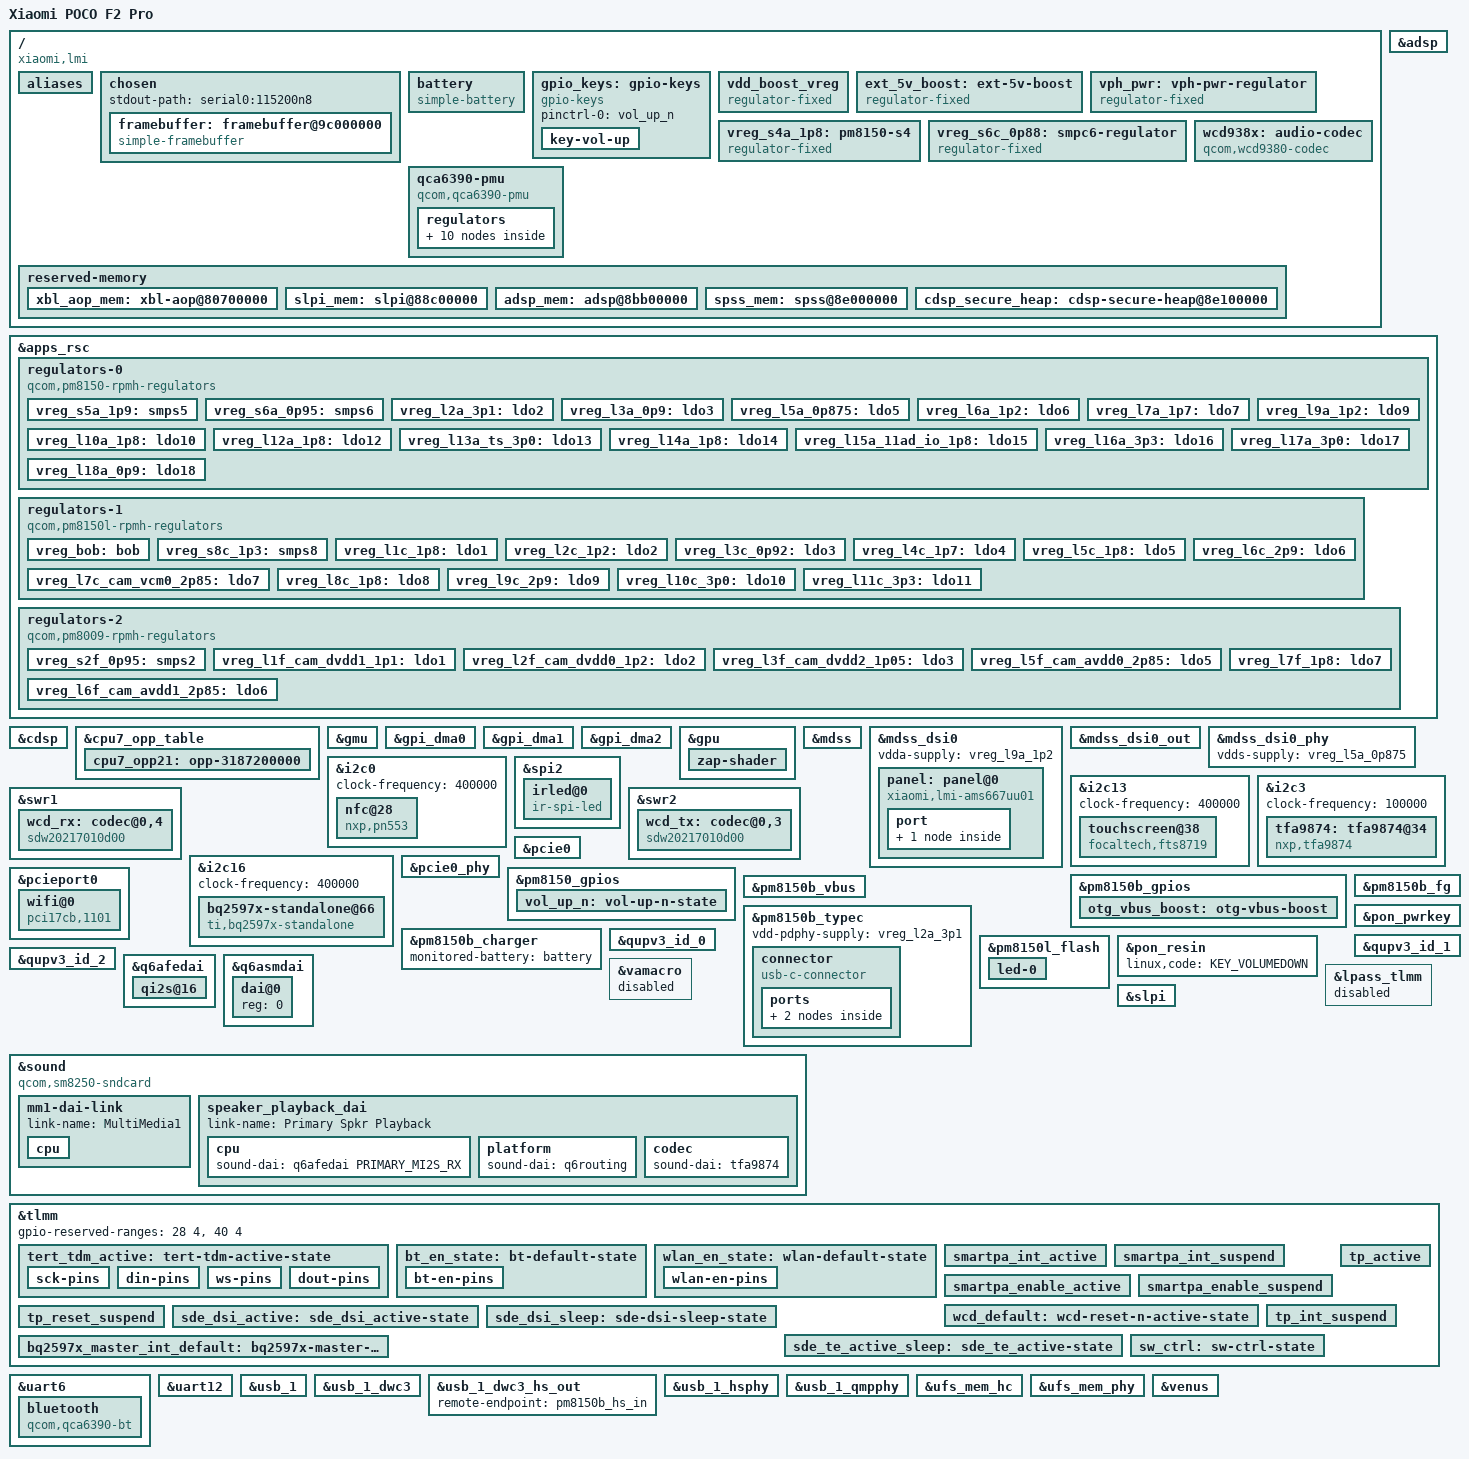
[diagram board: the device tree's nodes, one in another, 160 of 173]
// SPDX-License-Identifier: GPL-2.0-only OR BSD-2-Clause
/*
 * Copyright (c) 2025 Vitalii Skorkin <nikroks@mainlining.org>
 */

/dts-v1/;

#include <dt-bindings/arm/qcom,ids.h>
#include <dt-bindings/leds/common.h>
#include <dt-bindings/media/video-interfaces.h>
#include <dt-bindings/phy/phy.h>
#include <dt-bindings/regulator/qcom,rpmh-regulator.h>
#include <dt-bindings/sound/qcom,q6afe.h>
#include <dt-bindings/sound/qcom,q6asm.h>
#include <dt-bindings/usb/pd.h>
#include "sm8250.dtsi"
#include "pm8150.dtsi"
#include "pm8150b.dtsi"
#include "pm8150l.dtsi"
#include "pm8009.dtsi"

/*
 * Delete following upstream (sm8250.dtsi) reserved
 * memory mappings which are different on this device.
 */
/delete-node/ &adsp_mem;
/delete-node/ &cdsp_secure_heap;
/delete-node/ &slpi_mem;
/delete-node/ &spss_mem;
/delete-node/ &xbl_aop_mem;

/ {

	model = "Xiaomi POCO F2 Pro";
	compatible = "xiaomi,lmi", "qcom,sm8250";
	chassis-type = "handset";

	/* required for bootloader to select correct board */
	qcom,msm-id = <QCOM_ID_SM8250 0x20001>; /* SM8250 v2.1 */
	qcom,board-id = <37 0>;

	aliases {
		serial0 = &uart12;
     serial1 = &uart6;
	};

	chosen {
		#address-cells = <2>;
		#size-cells = <2>;
		ranges;
   stdout-path = "serial0:115200n8";
    
   framebuffer: framebuffer@9c000000 {
			compatible = "simple-framebuffer";
			reg = <0x0 0x9c000000 0x0 0x2300000>;
			width = <1080>;
			height = <2400>;
			stride = <(1080 * 4)>;
			format = "a8r8g8b8";
		};
	};

	battery: battery {
		compatible = "simple-battery";
		charge-full-design-microamp-hours = <4700000>;
		energy-full-design-microwatt-hours = <17500000>;
		voltage-min-design-microvolt = <3400000>;
		voltage-max-design-microvolt = <4460000>;
	};

	gpio_keys: gpio-keys {
		compatible = "gpio-keys";

		pinctrl-0 = <&vol_up_n>;
		pinctrl-names = "default";

		key-vol-up {
			label = "Volume Up";
			gpios = <&pm8150_gpios 6 GPIO_ACTIVE_LOW>;
			linux,code = <KEY_VOLUMEUP>;
			debounce-interval = <15>;
			linux,can-disable;
			wakeup-source;
		};
	};
  
  vdd_boost_vreg: vdd_boost_vreg {
		compatible = "regulator-fixed";
		regulator-name = "vdd_boost_vreg";
		regulator-min-microvolt = <5000000>;
		regulator-max-microvolt = <5000000>;
		startup-delay-us = <4000>;
		enable-active-high;
		regulator-always-on;
		gpio = <&pm8150b_gpios 5 0>;
	 };

	ext_5v_boost: ext-5v-boost {
		status = "okay";
		compatible = "regulator-fixed";
		gpio = <&pm8150b_gpios 12 GPIO_ACTIVE_HIGH>;
		pinctrl-names = "default";
		pinctrl-0 = <&otg_vbus_boost>;
		regulator-min-microvolt = <5000000>;
		regulator-max-microvolt = <5000000>;
		regulator-enable-ramp-delay = <1600>;
		regulator-name = "ext_5v_boost";
		enable-active-high;
	};

	vph_pwr: vph-pwr-regulator {
		compatible = "regulator-fixed";
		regulator-name = "vph_pwr";
		regulator-min-microvolt = <3700000>;
		regulator-max-microvolt = <3700000>;
	};
   
   vreg_s4a_1p8: pm8150-s4 {
		compatible = "regulator-fixed";
		regulator-name = "vreg_s4a_1p8";

		regulator-min-microvolt = <1800000>;
		regulator-max-microvolt = <1800000>;

		regulator-always-on;
		regulator-boot-on;

		vin-supply = <&vph_pwr>;
	};

	/* S6c is really ebi.lvl but it's there for supply map completeness sake. */
	vreg_s6c_0p88: smpc6-regulator {
		compatible = "regulator-fixed";
		regulator-name = "vreg_s6c_0p88";
		regulator-min-microvolt = <880000>;
		regulator-max-microvolt = <880000>;
		regulator-always-on;
		vin-supply = <&vph_pwr>;
	};
  
   wcd938x: audio-codec {
		compatible = "qcom,wcd9380-codec";
		
		pinctrl-names = "default";
		pinctrl-0 = <&wcd_default>;
		
		qcom,micbias1-microvolt = <2750000>;
		qcom,micbias2-microvolt = <2750000>;
		qcom,micbias3-microvolt = <2750000>;
		qcom,micbias4-microvolt = <2750000>;
		qcom,mbhc-buttons-vthreshold-microvolt = <75000 150000 237000 500000 500000 500000 500000 500000>;
		qcom,mbhc-headset-vthreshold-microvolt = <1700000>;
		qcom,mbhc-headphone-vthreshold-microvolt = <50000>;
		qcom,rx-device = <&wcd_rx>;
		qcom,tx-device = <&wcd_tx>;
		
		reset-gpios = <&tlmm 108 GPIO_ACTIVE_LOW>;
		
		vdd-buck-supply = <&vreg_s4a_1p8>;
		vdd-rxtx-supply = <&vreg_s4a_1p8>;
		vdd-io-supply = <&vreg_s4a_1p8>;
		vdd-mic-bias-supply = <&vreg_bob>;
		
		#sound-dai-cells = <1>;
	};

	qca6390-pmu {
		compatible = "qcom,qca6390-pmu";

		pinctrl-names = "default";
		pinctrl-0 = <&bt_en_state>, <&wlan_en_state>;

		vddaon-supply = <&vreg_s6a_0p95>;
		vddpmu-supply = <&vreg_s2f_0p95>;
		vddrfa0p95-supply = <&vreg_s2f_0p95>;
		vddrfa1p3-supply = <&vreg_s8c_1p3>;
		vddrfa1p9-supply = <&vreg_s5a_1p9>;
		vddpcie1p3-supply = <&vreg_s8c_1p3>;
		vddpcie1p9-supply = <&vreg_s5a_1p9>;
		vddio-supply = <&vreg_s4a_1p8>;

		wlan-enable-gpios = <&tlmm 20 GPIO_ACTIVE_HIGH>;
		bt-enable-gpios = <&tlmm 21 GPIO_ACTIVE_HIGH>;

		regulators {
			vreg_pmu_rfa_cmn: ldo0 {
				regulator-name = "vreg_pmu_rfa_cmn";
			};

			vreg_pmu_aon_0p59: ldo1 {
				regulator-name = "vreg_pmu_aon_0p59";
			};

			vreg_pmu_wlcx_0p8: ldo2 {
				regulator-name = "vreg_pmu_wlcx_0p8";
			};

			vreg_pmu_wlmx_0p85: ldo3 {
				regulator-name = "vreg_pmu_wlmx_0p85";
			};

			vreg_pmu_btcmx_0p85: ldo4 {
				regulator-name = "vreg_pmu_btcmx_0p85";
			};

			vreg_pmu_rfa_0p8: ldo5 {
				regulator-name = "vreg_pmu_rfa_0p8";
			};

			vreg_pmu_rfa_1p2: ldo6 {
				regulator-name = "vreg_pmu_rfa_1p2";
			};

			vreg_pmu_rfa_1p7: ldo7 {
				regulator-name = "vreg_pmu_rfa_1p7";
			};

			vreg_pmu_pcie_0p9: ldo8 {
				regulator-name = "vreg_pmu_pcie_0p9";
			};

			vreg_pmu_pcie_1p8: ldo9 {
				regulator-name = "vreg_pmu_pcie_1p8";
			};
		};
	};

	reserved-memory {
		xbl_aop_mem: xbl-aop@80700000 {
			reg = <0x0 0x80600000 0x0 0x260000>;
			no-map;
		};

		slpi_mem: slpi@88c00000 {
			reg = <0x0 0x88c00000 0x0 0x2f00000>;
			no-map;
		};

		adsp_mem: adsp@8bb00000 {
			reg = <0x0 0x8bb00000 0x0 0x2500000>;
			no-map;
		};

		spss_mem: spss@8e000000 {
			reg = <0x0 0x8e000000 0x0 0x100000>;
			no-map;
		};

		cdsp_secure_heap: cdsp-secure-heap@8e100000 {
			reg = <0x0 0x8e100000 0x0 0x4600000>;
			no-map;
		};
	};
};

&adsp {
	firmware-name = "qcom/sm8250/xiaomi/alioth/adsp.mbn";
	status = "okay";
};

&apps_rsc {
	regulators-0 {
		compatible = "qcom,pm8150-rpmh-regulators";
		qcom,pmic-id = "a";

		vdd-s1-supply = <&vph_pwr>;
		vdd-s2-supply = <&vph_pwr>;
		vdd-s3-supply = <&vph_pwr>;
		vdd-s4-supply = <&vph_pwr>;
		vdd-s5-supply = <&vph_pwr>;
		vdd-s6-supply = <&vph_pwr>;
		vdd-s7-supply = <&vph_pwr>;
		vdd-s8-supply = <&vph_pwr>;
		vdd-s9-supply = <&vph_pwr>;
		vdd-s10-supply = <&vph_pwr>;
		vdd-l1-l8-l11-supply = <&vreg_s6c_0p88>;
		vdd-l2-l10-supply = <&vreg_bob>;
		vdd-l3-l4-l5-l18-supply = <&vreg_s6a_0p95>;
		vdd-l6-l9-supply = <&vreg_s8c_1p3>;
		vdd-l7-l12-l14-l15-supply = <&vreg_s5a_1p9>;
		vdd-l13-l16-l17-supply = <&vreg_bob>;

		vreg_s5a_1p9: smps5 {
			regulator-name = "vreg_s5a_1p9";
			regulator-min-microvolt = <1904000>;
			regulator-max-microvolt = <2000000>;
			regulator-initial-mode = <RPMH_REGULATOR_MODE_HPM>;
		};

		vreg_s6a_0p95: smps6 {
			regulator-name = "vreg_s6a_0p95";
			regulator-min-microvolt = <920000>;
			regulator-max-microvolt = <1128000>;
			regulator-initial-mode = <RPMH_REGULATOR_MODE_HPM>;
		};

		vreg_l2a_3p1: ldo2 {
			regulator-name = "vreg_l2a_3p1";
			regulator-min-microvolt = <3072000>;
			regulator-max-microvolt = <3072000>;
			regulator-initial-mode = <RPMH_REGULATOR_MODE_HPM>;
		};

		vreg_l3a_0p9: ldo3 {
			regulator-name = "vreg_l3a_0p9";
			regulator-min-microvolt = <928000>;
			regulator-max-microvolt = <932000>;
			regulator-initial-mode = <RPMH_REGULATOR_MODE_HPM>;
		};

		vreg_l5a_0p875: ldo5 {
			regulator-name = "vreg_l5a_0p875";
			regulator-min-microvolt = <880000>;
			regulator-max-microvolt = <880000>;
			regulator-initial-mode = <RPMH_REGULATOR_MODE_HPM>;
		};

		vreg_l6a_1p2: ldo6 {
			regulator-name = "vreg_l6a_1p2";
			regulator-min-microvolt = <1200000>;
			regulator-max-microvolt = <1200000>;
			regulator-initial-mode = <RPMH_REGULATOR_MODE_HPM>;
		};

		vreg_l7a_1p7: ldo7 {
			regulator-name = "vreg_l7a_1p7";
			regulator-min-microvolt = <1704000>;
			regulator-max-microvolt = <1800000>;
			regulator-initial-mode = <RPMH_REGULATOR_MODE_HPM>;
		};

		vreg_l9a_1p2: ldo9 {
			regulator-name = "vreg_l9a_1p2";
			regulator-min-microvolt = <1200000>;
			regulator-max-microvolt = <1200000>;
			regulator-initial-mode = <RPMH_REGULATOR_MODE_HPM>;
		};

		vreg_l10a_1p8: ldo10 {
			regulator-name = "vreg_l10a_1p8";
			regulator-min-microvolt = <1800000>;
			regulator-max-microvolt = <1800000>;
			regulator-initial-mode = <RPMH_REGULATOR_MODE_HPM>;
		};

		vreg_l12a_1p8: ldo12 {
			regulator-name = "vreg_l12a_1p8";
			regulator-min-microvolt = <1800000>;
			regulator-max-microvolt = <1800000>;
			regulator-initial-mode = <RPMH_REGULATOR_MODE_HPM>;
		};

		vreg_l13a_ts_3p0: ldo13 {
			regulator-name = "vreg_l13a_ts_3p0";
			regulator-min-microvolt = <3008000>;
			regulator-max-microvolt = <3008000>;
			regulator-initial-mode = <RPMH_REGULATOR_MODE_HPM>;
		};

		vreg_l14a_1p8: ldo14 {
			regulator-name = "vreg_l14a_1p8";
			regulator-min-microvolt = <1800000>;
			regulator-max-microvolt = <1880000>;
			regulator-initial-mode = <RPMH_REGULATOR_MODE_HPM>;
		};

		vreg_l15a_11ad_io_1p8: ldo15 {
			regulator-name = "vreg_l15a_11ad_io_1p8";
			regulator-min-microvolt = <1800000>;
			regulator-max-microvolt = <1800000>;
			regulator-initial-mode = <RPMH_REGULATOR_MODE_HPM>;
		};

		vreg_l16a_3p3: ldo16 {
			regulator-name = "vreg_l16a_3p3";
			regulator-min-microvolt = <3024000>;
			regulator-max-microvolt = <3304000>;
			regulator-initial-mode = <RPMH_REGULATOR_MODE_HPM>;
		};

		vreg_l17a_3p0: ldo17 {
			regulator-name = "vreg_l17a_3p0";
			regulator-min-microvolt = <2856000>;
			regulator-max-microvolt = <3008000>;
			regulator-initial-mode = <RPMH_REGULATOR_MODE_HPM>;
		};

		vreg_l18a_0p9: ldo18 {
			regulator-name = "vreg_l18a_0p9";
			regulator-min-microvolt = <912000>;
			regulator-max-microvolt = <912000>;
			regulator-initial-mode = <RPMH_REGULATOR_MODE_HPM>;
		};
	};

	regulators-1 {
		compatible = "qcom,pm8150l-rpmh-regulators";
		qcom,pmic-id = "c";

		vdd-s1-supply = <&vph_pwr>;
		vdd-s2-supply = <&vph_pwr>;
		vdd-s3-supply = <&vph_pwr>;
		vdd-s4-supply = <&vph_pwr>;
		vdd-s5-supply = <&vph_pwr>;
		vdd-s6-supply = <&vph_pwr>;
		vdd-s7-supply = <&vph_pwr>;
		vdd-s8-supply = <&vph_pwr>;
		vdd-l1-l8-supply = <&vreg_s4a_1p8>;
		vdd-l2-l3-supply = <&vreg_s8c_1p3>;
		vdd-l4-l5-l6-supply = <&vreg_bob>;
		vdd-l7-l11-supply = <&vreg_bob>;
		vdd-l9-l10-supply = <&vreg_bob>;
		vdd-bob-supply = <&vph_pwr>;

		vreg_bob: bob {
			regulator-name = "vreg_bob";
			regulator-min-microvolt = <3008000>;
			regulator-max-microvolt = <4000000>;
			regulator-initial-mode = <RPMH_REGULATOR_MODE_AUTO>;
		};

		vreg_s8c_1p3: smps8 {
			regulator-name = "vreg_s8c_1p3";
			regulator-min-microvolt = <1352000>;
			regulator-max-microvolt = <1352000>;
			regulator-initial-mode = <RPMH_REGULATOR_MODE_HPM>;
		};

		vreg_l1c_1p8: ldo1 {
			regulator-name = "vreg_l1c_1p8";
			regulator-min-microvolt = <1800000>;
			regulator-max-microvolt = <1800000>;
			regulator-initial-mode = <RPMH_REGULATOR_MODE_HPM>;
			// regulator-always-on;
			// regulator-boot-on;
		};

		vreg_l2c_1p2: ldo2 {
			regulator-name = "vreg_l2c_1p2";
			regulator-min-microvolt = <1200000>;
			regulator-max-microvolt = <1200000>;
			regulator-initial-mode = <RPMH_REGULATOR_MODE_HPM>;
		};

		vreg_l3c_0p92: ldo3 {
			regulator-name = "vreg_l3c_0p92";
			regulator-min-microvolt = <920000>;
			regulator-max-microvolt = <920000>;
			regulator-initial-mode = <RPMH_REGULATOR_MODE_HPM>;
		};

		vreg_l4c_1p7: ldo4 {
			regulator-name = "vreg_l4c_1p7";
			regulator-min-microvolt = <1704000>;
			regulator-max-microvolt = <2928000>;
			regulator-initial-mode = <RPMH_REGULATOR_MODE_HPM>;
		};

		vreg_l5c_1p8: ldo5 {
			regulator-name = "vreg_l5c_1p8";
			regulator-min-microvolt = <1800000>;
			regulator-max-microvolt = <2928000>;
			regulator-initial-mode = <RPMH_REGULATOR_MODE_HPM>;
		};

		vreg_l6c_2p9: ldo6 {
			regulator-name = "vreg_l6c_2p9";
			regulator-min-microvolt = <1800000>;
			regulator-max-microvolt = <2960000>;
			regulator-initial-mode = <RPMH_REGULATOR_MODE_HPM>;
		};

		vreg_l7c_cam_vcm0_2p85: ldo7 {
			regulator-name = "vreg_l7c_cam_vcm0_2p85";
			regulator-min-microvolt = <2856000>;
			regulator-max-microvolt = <3104000>;
			regulator-initial-mode = <RPMH_REGULATOR_MODE_HPM>;
		};

		vreg_l8c_1p8: ldo8 {
			regulator-name = "vreg_l8c_1p8";
			regulator-min-microvolt = <1800000>;
			regulator-max-microvolt = <1800000>;
			regulator-initial-mode = <RPMH_REGULATOR_MODE_HPM>;
		};

		vreg_l9c_2p9: ldo9 {
			regulator-name = "vreg_l9c_2p9";
			regulator-min-microvolt = <2704000>;
			regulator-max-microvolt = <2960000>;
			regulator-initial-mode = <RPMH_REGULATOR_MODE_HPM>;
		};

		vreg_l10c_3p0: ldo10 {
			regulator-name = "vreg_l10c_3p0";
			regulator-min-microvolt = <3000000>;
			regulator-max-microvolt = <3000000>;
			regulator-initial-mode = <RPMH_REGULATOR_MODE_HPM>;
		};

		vreg_l11c_3p3: ldo11 {
			regulator-name = "vreg_l11c_3p3";
			regulator-min-microvolt = <3000000>;
			regulator-max-microvolt = <3312000>;
			regulator-initial-mode = <RPMH_REGULATOR_MODE_HPM>;
		};
	};

	regulators-2 {
		compatible = "qcom,pm8009-rpmh-regulators";
		qcom,pmic-id = "f";

		vdd-s1-supply = <&vph_pwr>;
		vdd-s2-supply = <&vreg_bob>;
		vdd-l2-supply = <&vreg_s8c_1p3>;
		vdd-l5-l6-supply = <&vreg_bob>;
		vdd-l7-supply = <&vreg_s4a_1p8>;

		vreg_s2f_0p95: smps2 {
			regulator-name = "vreg_s2f_0p95";
			regulator-min-microvolt = <900000>;
			regulator-max-microvolt = <952000>;
			regulator-initial-mode = <RPMH_REGULATOR_MODE_AUTO>;
		};

		vreg_l1f_cam_dvdd1_1p1: ldo1 {
			regulator-name = "vreg_l1f_cam_dvdd1_1p1";
			regulator-min-microvolt = <1104000>;
			regulator-max-microvolt = <1104000>;
			regulator-initial-mode = <RPMH_REGULATOR_MODE_HPM>;
		};

		vreg_l2f_cam_dvdd0_1p2: ldo2 {
			regulator-name = "vreg_l2f_cam_dvdd0_1p2";
			regulator-min-microvolt = <1200000>;
			regulator-max-microvolt = <1200000>;
			regulator-initial-mode = <RPMH_REGULATOR_MODE_HPM>;
		};

		vreg_l3f_cam_dvdd2_1p05: ldo3 {
			regulator-name = "vreg_l3f_cam_dvdd2_1p05";
			regulator-min-microvolt = <1056000>;
			regulator-max-microvolt = <1056000>;
			regulator-initial-mode = <RPMH_REGULATOR_MODE_HPM>;
		};

		vreg_l5f_cam_avdd0_2p85: ldo5 {
			regulator-name = "vreg_l5f_cam_avdd0_2p85";
			regulator-min-microvolt = <2800000>;
			regulator-max-microvolt = <2800000>;
			regulator-initial-mode = <RPMH_REGULATOR_MODE_HPM>;
		};

		vreg_l6f_cam_avdd1_2p85: ldo6 {
			regulator-name = "vreg_l6f_cam_avdd1_2p85";
			regulator-min-microvolt = <2856000>;
			regulator-max-microvolt = <2856000>;
			regulator-initial-mode = <RPMH_REGULATOR_MODE_HPM>;
		};

		vreg_l7f_1p8: ldo7 {
			regulator-name = "vreg_l7f_1p8";
			regulator-min-microvolt = <1800000>;
			regulator-max-microvolt = <1800000>;
			regulator-initial-mode = <RPMH_REGULATOR_MODE_HPM>;
		};
	};
};

&cdsp {
	firmware-name = "qcom/sm8250/xiaomi/alioth/cdsp.mbn";
	status = "okay";
};

// SD870 additional cpu frequency
&cpu7_opp_table {
	cpu7_opp21: opp-3187200000 {
		opp-hz = /bits/ 64 <3187200000>;
		opp-peak-kBps = <8368000 51609600>;
	};
};

&gmu {
	status = "okay";
};

&gpi_dma0 {
	status = "okay";
};

&gpi_dma1 {
	status = "okay";
};

&gpi_dma2 {
	status = "okay";
};

&gpu {
	status = "okay";

	zap-shader {
		memory-region = <&gpu_mem>;
		firmware-name = "qcom/sm8250/xiaomi/alioth/a650_zap.mbn";
	};
};

&mdss {
	status = "okay";
};

&mdss_dsi0 {
	vdda-supply = <&vreg_l9a_1p2>;
	status = "okay";

	panel: panel@0 {
		compatible = "xiaomi,lmi-ams667uu01";
		reg = <0>;

		pinctrl-0 = <&sde_dsi_active &sde_te_active_sleep>;
		pinctrl-1 = <&sde_dsi_sleep &sde_te_active_sleep>;
		pinctrl-names = "default", "sleep";

		vddio-supply = <&vreg_l14a_1p8>;
		vci-supply = <&vreg_l10c_3p0>;
		reset-gpios = <&tlmm 46 GPIO_ACTIVE_LOW>;

		port {
			panel_in: endpoint {
				remote-endpoint = <&mdss_dsi0_out>;
			};
		};
	};
};

&mdss_dsi0_out {
	remote-endpoint = <&panel_in>;
	data-lanes = <0 1 2 3>;
};

&mdss_dsi0_phy {
	vdds-supply = <&vreg_l5a_0p875>;
	status = "okay";
};

&i2c0 {
	status = "okay";
	clock-frequency = <400000>;

	nfc@28 {
		compatible = "nxp,pn553",
			     "nxp,nxp-nci-i2c";
		reg = <0x28>;

		interrupt-parent = <&tlmm>;
		interrupts = <111 IRQ_TYPE_EDGE_RISING>;

		enable-gpios = <&tlmm 83 GPIO_ACTIVE_HIGH>;
		firmware-gpios = <&tlmm 110 GPIO_ACTIVE_HIGH>;
	};
};

&spi2 {
	status = "okay";
	pinctrl-names = "default";
	pinctrl-0 = <&qup_spi2_data_clk>;
	clock-frequency = <50000000>;

	irled@0 {
		compatible = "ir-spi-led";
		reg = <0x0>;

		spi-max-frequency = <19200000>;
		power-supply = <&vph_pwr>;
		duty-cycle = /bits/ 8 <60>;
		led-active-low;
	};
};

&i2c13 {
	clock-frequency = <400000>;
	status = "okay";

	touchscreen@38 {
		compatible = "focaltech,fts8719";
		reg = <0x38>;

		pinctrl-0 = <&tp_active>;
   pinctrl-1 = <&tp_int_suspend &tp_reset_suspend>;
		pinctrl-names = "default";

		interrupts-extended = <&tlmm 39 IRQ_TYPE_EDGE_FALLING>;
    reset-gpios = <&tlmm 38 GPIO_ACTIVE_LOW>;
    irq-gpio = <&tlmm 39 GPIO_TRANSITORY>; 
    touchscreen-size-x = <1080>;
		touchscreen-size-y = <2400>;
    max-touch-number = <10>;
    avdd-supply = <&vreg_l10c_3p0>;
    vddio-supply = <&vreg_l1c_1p8>;
	};
};

&i2c3 {
    #address-cells = <1>;
	#size-cells = <0>;
	clock-frequency = <100000>;
	status = "ok";
	
	tfa9874: tfa9874@34 {
		compatible = "nxp,tfa9874";
		reset-gpio = <&tlmm 114 0>;
		irq-gpio = <&tlmm 100 0>;
		interrupt-parent = <&tlmm>;
		interrupts = <100 0>;
		interrupt-names = "smartpa_irq";
		pinctrl-names = "default", "sleep";
		pinctrl-0 = <&smartpa_int_active &smartpa_enable_active>;
		pinctrl-1 = <&smartpa_int_suspend &smartpa_enable_suspend>;
		reg = <0x34>;
		sound-name-prefix = "Speaker";
		#sound-dai-cells = <0>;
	};
};

&swr1 {
	status = "okay";
	/* WCD9380 RX */
	wcd_rx: codec@0,4 {
		compatible = "sdw20217010d00";
		reg = <0 4>;
		qcom,rx-port-mapping = <1 2 3 4 5>;
	};
};

&swr2 {
	status = "okay";
	/* WCD9380 TX */
	wcd_tx: codec@0,3 {
		compatible = "sdw20217010d00";
		reg = <0 3>;
		qcom,tx-port-mapping = <2 2 3 4>;
	};
};

&i2c16 {
	clock-frequency = <400000>;
	status = "okay";
	bq2597x-standalone@66 {
		compatible = "ti,bq2597x-standalone";
		reg = <0x66>;
		interrupt-parent = <&tlmm>;
		interrupts = <157 0x2002>;
		pinctrl-names = "default";
		pinctrl-0 = <&bq2597x_master_int_default>;
		/*ti,bq2597x,bat-ovp-disable;*/
		ti,bq2597x,bat-ovp-alarm-disable;
		ti,bq2597x,bat-ocp-disable;
		ti,bq2597x,bat-ocp-alarm-disable;
		ti,bq2597x,bat-ucp-alarm-disable;
		ti,bq2597x,bat-ucp-disable;
		/*ti,bq2597x,bus-ovp-alarm-disable;
		ti,bq2597x,bus-ocp-disable;
		ti,bq2597x,bus-ocp-alarm-disable;*/
		ti,bq2597x,bat-therm-disable;
		ti,bq2597x,bus-therm-disable;
		ti,bq2597x,die-therm-disable;
		ti,bq2597x,bat-ovp-threshold = <4550>;
		ti,bq2597x,bat-ovp-alarm-threshold = <4525>;
		//ti,bq2597x,bat-ocp-threshold = <8000>;
		//ti,bq2597x,bat-ocp-alarm-threshold = <7500>;
		ti,bq2597x,bus-ovp-threshold = <12000>;
		ti,bq2597x,bus-ovp-alarm-threshold = <11000>;
		ti,bq2597x,bus-ocp-threshold = <3800>;
		ti,bq2597x,bus-ocp-alarm-threshold = <3500>;

		//ti,bq2597x,bat-ucp-alarm-threshold = <2000>;
		ti,bq2597x,bat-therm-threshold = <0x15>;/*4.1%*/
		ti,bq2597x,bus-therm-threshold = <0x15>;/*4.1%*/
		ti,bq2597x,die-therm-threshold = <145>;
		ti,bq2597x,ac-ovp-threshold = <14>;
		//ti,bq2597x,sense-resistor-mohm = <2>;

		sc8551,ac-ovp-threshold = <14>;
	};
};

&pcie0 {
	status = "okay";
};

&pcie0_phy {
	vdda-phy-supply = <&vreg_l5a_0p875>;
	vdda-pll-supply = <&vreg_l9a_1p2>;
	status = "okay";
};

&pcieport0 {
	wifi@0 {
		compatible = "pci17cb,1101";
		reg = <0x10000 0x0 0x0 0x0 0x0>;

		vddrfacmn-supply = <&vreg_pmu_rfa_cmn>;
		vddaon-supply = <&vreg_pmu_aon_0p59>;
		vddwlcx-supply = <&vreg_pmu_wlcx_0p8>;
		vddwlmx-supply = <&vreg_pmu_wlmx_0p85>;
		vddrfa0p8-supply = <&vreg_pmu_rfa_0p8>;
		vddrfa1p2-supply = <&vreg_pmu_rfa_1p2>;
		vddrfa1p7-supply = <&vreg_pmu_rfa_1p7>;
		vddpcie0p9-supply = <&vreg_pmu_pcie_0p9>;
		vddpcie1p8-supply = <&vreg_pmu_pcie_1p8>;
	};
};

&pm8150_gpios {
	vol_up_n: vol-up-n-state {
		pins = "gpio6";
		function = "normal";
		power-source = <1>;
		input-enable;
		bias-pull-up;
	};
};

&pm8150b_gpios {
	otg_vbus_boost: otg-vbus-boost {
		pins = "gpio12";
		function = "normal";
		power-source = <0x00>;
		output-low;
	};
};

&pm8150b_vbus {
	regulator-min-microamp = <500000>;
	regulator-max-microamp = <3000000>;
	status = "okay";
};

&pm8150b_typec {
	vdd-pdphy-supply = <&vreg_l2a_3p1>;
	status = "okay";

	connector {
		compatible = "usb-c-connector";

		op-sink-microwatt = <10000000>;
		power-role = "dual";
		data-role = "dual";
		self-powered;

		source-pdos = <PDO_FIXED(5000, 3000,
					 PDO_FIXED_DUAL_ROLE |
					 PDO_FIXED_USB_COMM |
					 PDO_FIXED_DATA_SWAP)>;

		sink-pdos = <PDO_FIXED(5000, 3000,
				       PDO_FIXED_DUAL_ROLE |
				       PDO_FIXED_USB_COMM |
				       PDO_FIXED_DATA_SWAP)
				       PDO_VAR(5000, 12000, 5000)>;

		ports {
			#address-cells = <1>;
			#size-cells = <0>;

			port@0 {
				reg = <0>;

				pm8150b_hs_in: endpoint {
					remote-endpoint = <&usb_1_dwc3_hs_out>;
				};
			};
		};
	};
};

&pm8150b_fg {
	status = "okay";
	monitored-battery = <&battery>;
	power-supplies = <&pm8150b_charger>;
};

&pm8150b_charger {
	status = "okay";
	monitored-battery = <&battery>;
};

&pm8150l_flash {
	status = "okay";

	led-0 {
		function = LED_FUNCTION_FLASH;
		color = <LED_COLOR_ID_WHITE>;
		led-sources = <1>;
		led-max-microamp = <300000>;
		flash-max-microamp = <1000000>;
		flash-max-timeout-us = <1280000>;
	};
};

&pon_pwrkey {
	status = "okay";
};

&pon_resin {
	linux,code = <KEY_VOLUMEDOWN>;
	status = "okay";
};

&qupv3_id_0 {
	status = "okay";
};

&qupv3_id_1 {
	status = "okay";
};

&qupv3_id_2 {
	status = "okay";
};

&q6afedai {
	qi2s@16 {
		reg = <PRIMARY_MI2S_RX>;
		qcom,sd-lines = <0>;
	};
};

&q6asmdai {
	dai@0 {
		reg = <0>;
	};
};

&vamacro {
	status = "disabled";
};

&lpass_tlmm {
	status = "disabled";
};

&sound {
		compatible = "qcom,sm8250-sndcard";
		pinctrl-0 = <&pri_mi2s_active>;
		pinctrl-names = "default";
		model = "Xiaomi lmi";

		mm1-dai-link {
			link-name = "MultiMedia1";
			cpu {
				sound-dai = <&q6asmdai MSM_FRONTEND_DAI_MULTIMEDIA1>;
			};
		};

		speaker_playback_dai {
			link-name = "Primary Spkr Playback";
			cpu {
				sound-dai = <&q6afedai PRIMARY_MI2S_RX>;
			};

			platform {
				sound-dai = <&q6routing>;
			};

			codec {
				sound-dai = <&tfa9874>;
		};
	};
};


&slpi {
	firmware-name = "qcom/sm8250/xiaomi/alioth/slpi.mbn";
	status = "okay";
};

&tlmm {
	gpio-reserved-ranges = <28 4>, <40 4>;

	tert_tdm_active: tert-tdm-active-state {
		sck-pins {
			pins = "gpio133";
			function = "mi2s2_sck";
			drive-strength = <8>;
			bias-disable;
			output-high;
		};

		din-pins {
			pins = "gpio134";
			function = "mi2s2_data0";
			drive-strength = <8>;
			bias-disable;
		};

		ws-pins {
			pins = "gpio135";
			function = "mi2s2_ws";
			drive-strength = <8>;
			bias-disable;
			output-high;
		};

		dout-pins {
			pins = "gpio137";
			function = "mi2s2_data1";
			drive-strength = <8>;
			bias-disable;
		};
	};

	bt_en_state: bt-default-state {
		bt-en-pins {
			pins = "gpio21";
			function = "gpio";
			drive-strength = <16>;
			output-low;
			bias-pull-up;
		};
	};

	wlan_en_state: wlan-default-state {
		wlan-en-pins {
			pins = "gpio20";
			function = "gpio";
			drive-strength = <16>;
			output-low;
			bias-pull-up;
		};
	};

	smartpa_int_active: smartpa_int_active {
			pins = "gpio100";
			function = "gpio";
			drive-strength = <2>;
			bias-pull-up;
			input-enable;
	};

	smartpa_int_suspend: smartpa_int_suspend {
			pins = "gpio100";
			function = "gpio";
			drive-strength = <2>;
			bias-pull-up;
			input-enable;
	};

	smartpa_enable_active: smartpa_enable_active {
			pins = "gpio114";
			function = "gpio";
			drive-strength = <2>;
			bias-disable;
			bias-pull-down;
			output-low;
	};

	smartpa_enable_suspend: smartpa_enable_suspend {
			pins = "gpio114";
			function = "gpio";
			drive-strength = <2>;
			bias-disable;
			bias-pull-down;
			output-low;
	};
	
   wcd_default: wcd-reset-n-active-state {
		pins = "gpio108";
		function = "gpio";
		drive-strength = <16>;
		bias-disable;
		output-low;
	};

	tp_active: tp_active {
			pins = "gpio38", "gpio39", "gpio72";
			function = "gpio";
			drive-strength = <16>;
			bias-pull-up;
	};
	
	tp_int_suspend: tp_int_suspend {
			pins = "gpio39";
			function = "gpio";
			drive-strength = <16>;
			input-enable;
			bias-pull-up;
	};

	tp_reset_suspend: tp_reset_suspend {
			pins = "gpio38";
			function = "gpio";
			drive-strength = <16>;
			bias-disable;
	};

	sde_dsi_active: sde_dsi_active-state {
		pins = "gpio46";
		function = "gpio";
		drive-strength = <8>;
		bias-disable;
		output-high;
	};

	sde_dsi_sleep: sde-dsi-sleep-state {
		pins = "gpio46";
		function = "gpio";
		drive-strength = <2>;
		bias-pull-down;
		output-high;
	};

	sde_te_active_sleep: sde_te_active-state {
		pins = "gpio46";
		function = "mdp_vsync";
		drive-strength = <2>;
		bias-pull-down;
	};
  
   bq2597x_master_int_default: bq2597x-master-int-default {
		pins = "gpio157";
		function = "gpio";
		drive-strength = <2>;
		bias-pull-up;
		input-enable;
	}; 

	sw_ctrl: sw-ctrl-state {
		pins = "gpio124";
		function = "gpio";
		bias-pull-down;
	};
};

&uart6 {
	status = "okay";
	
	bluetooth {
		compatible = "qcom,qca6390-bt";
		vddrfacmn-supply = <&vreg_pmu_rfa_cmn>;
		vddaon-supply = <&vreg_pmu_aon_0p59>;
		vddbtcmx-supply = <&vreg_pmu_btcmx_0p85>;
		vddrfa0p8-supply = <&vreg_pmu_rfa_0p8>;
		vddrfa1p2-supply = <&vreg_pmu_rfa_1p2>;
		vddrfa1p7-supply = <&vreg_pmu_rfa_1p7>;
	};
};

&uart12 {
	status = "okay";
};

&usb_1 {
	status = "okay";
};

&usb_1_dwc3 {
	dr_mode = "otg";
	// dr_mode = "peripheral";
	usb-role-switch;
};

&usb_1_dwc3_hs_out {
	remote-endpoint = <&pm8150b_hs_in>;
};

&usb_1_hsphy {
	status = "okay";
	vdda-pll-supply = <&vreg_l5a_0p875>;
	vdda18-supply = <&vreg_l12a_1p8>;
	vdda33-supply = <&vreg_l2a_3p1>;
};

&usb_1_qmpphy {
	status = "okay";
	vdda-phy-supply = <&vreg_l9a_1p2>;
	vdda-pll-supply = <&vreg_l18a_0p9>;
};

&ufs_mem_hc {
	vcc-supply = <&vreg_l17a_3p0>;
	vcc-max-microamp = <800000>;
	vccq-supply = <&vreg_l6a_1p2>;
	vccq-max-microamp = <800000>;
	vccq2-supply = <&vreg_s4a_1p8>;
	vccq2-max-microamp = <800000>;
	status = "okay";
};

&ufs_mem_phy {
	vdda-phy-supply = <&vreg_l5a_0p875>;
	vdda-pll-supply = <&vreg_l9a_1p2>;
	status = "okay";
};

&venus {
	firmware-name = "qcom/sm8250/xiaomi/alioth/venus.mbn";
	status = "okay";
};
